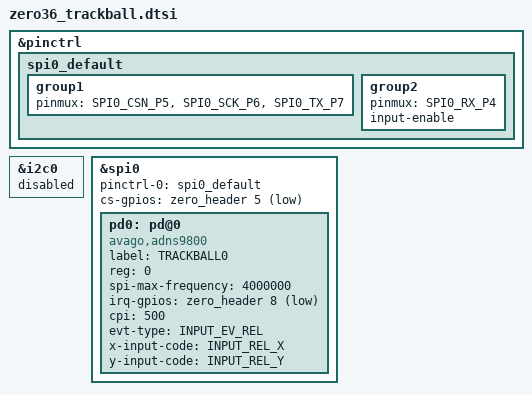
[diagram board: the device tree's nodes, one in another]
/*
 * Copyright (c) 2020 Pete Johanson
 *
 * SPDX-License-Identifier: MIT
 */

&pinctrl {
	spi0_default: spi0_default {
		group1 {
			pinmux = <SPI0_CSN_P5>, <SPI0_SCK_P6>, <SPI0_TX_P7>;
		};
		group2 {
			pinmux = <SPI0_RX_P4>;
			input-enable;
		};
	};
};

&i2c0 {
	status = "disabled";
};

&spi0 {
	status = "disabled"; // <<< disabled in main .dtsi, okay in .overlay
	pd0: pd@0 {
		compatible = "avago,adns9800";
		status = "disabled";
		label = "TRACKBALL0";
		reg = <0>;
		spi-max-frequency = <4000000>;
	};
};

// Config custom gpios
&spi0 {
  status = "okay";
	pinctrl-0 = <&spi0_default>;
	pinctrl-names = "default";
	cs-gpios = <&zero_header 5 GPIO_ACTIVE_LOW>;
};

#include <zephyr/dt-bindings/input/input-event-codes.h>

&pd0 {
  status = "okay";
  irq-gpios = <&zero_header 8 (GPIO_ACTIVE_LOW | GPIO_PULL_UP)>;
	cpi = <500>;
	evt-type = <INPUT_EV_REL>;
	x-input-code = <INPUT_REL_X>;
	y-input-code = <INPUT_REL_Y>;
};
